AUTOSAR XML (schema 4-0-3)
standard types defined: Boolean
package /AUTOSAR_Platform/DataConstrs
  range DC_Boolean: raw 0..1
package /PATAC/MSM/ComponentTypes
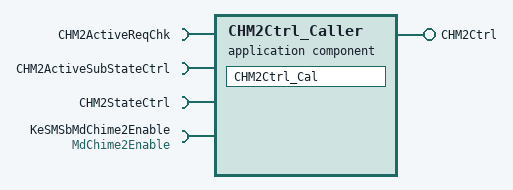
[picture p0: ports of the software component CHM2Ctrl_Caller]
  application sw component type CHM2Ctrl_Caller
    provide port CHM2Ctrl: server-com-spec{operation=CHM2Ctrl/Cal, queue-length=1}, provided-interface=CHM2Ctrl
    4 x require port:
      CHM2ActiveReqChk: client-com-spec=CHM2ActiveReqChk/Cal, required-interface=CHM2ActiveReqChk
      CHM2ActiveSubStateCtrl: client-com-spec=CHM2ActiveSubStateCtrl/Cal, required-interface=CHM2ActiveSubStateCtrl
      CHM2StateCtrl: client-com-spec=CHM2StateCtrl/Cal, required-interface=CHM2StateCtrl
      KeSMSbMdChime2Enable: parameter-require-com-spec{init-value=0, parameter=Val}, required-interface=MdChime2Enable
    behavior CHM2Ctrl_Caller_InternalBehavior
      operation invoked event OIT_CHM2Ctrl_Cal_CHM2Ctrl_Cal: start-on-event=CHM2Ctrl_Cal, operation=CHM2Ctrl.Cal
      runnable CHM2Ctrl_Cal
        parameter access PA_KeSMSbMdChime2Enable_Val: accessed-parameter=KeSMSbMdChime2Enable.Val
        sync call SC_CHM2ActiveReqChk_Cal: operation=CHM2ActiveReqChk.Cal, timeout=0
        sync call SC_CHM2ActiveSubStateCtrl_Cal: operation=CHM2ActiveSubStateCtrl.Cal, timeout=0
        sync call SC_CHM2StateCtrl_Cal: operation=CHM2StateCtrl.Cal, timeout=0
  swc implementation CHM2Ctrl_Caller_Implementation: behavior=CHM2Ctrl_Caller_InternalBehavior
    code-descriptors:
      code Default: artifact-descriptors=autosar-engineering-object={short-label=Default, category=SWSRC}
package /PATAC/MSM/ModeAdjust/CalPortInterface
  parameter interface MdChime2Enable
    parameter data prototype Val: sw-calibration-access=READ-WRITE, type=Boolean
package /PATAC/MSM/ModeAdjust/PortInterface
  4 x client server interface:
    CHM2ActiveReqChk
      operation Cal
    CHM2ActiveSubStateCtrl
      operation Cal
    CHM2Ctrl
      operation Cal
    CHM2StateCtrl
      operation Cal
